# PIC18F06Q20 register map
Vendor: Microchip
Registers are 8-bit, read-write, reset 0x0 unless marked. A register's access mark holds for its fields unless they carry their own. Addresses are absolute, and some are shared; only a register's first bit layout is shown; [hi:lo] are bit positions; {n}, {i} and the like mark numbered series.

## amp_fvr_ts_ctrl
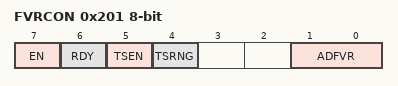
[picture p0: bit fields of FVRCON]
0x201 FVRCON reset not defined — (power-on value xx00--00)
  [7] EN — Zero-Cross Detect Software Enable bit
  [6] RDY ro
  [5] TSEN — Zero-Cross Detect Data Output
  [4] TSRNG — Zero-Cross Detect Polarity bit
  [1:0] ADFVR — Zero-Cross Detect Positive-going Edge Interrupt Enable

## lvd_ctrl
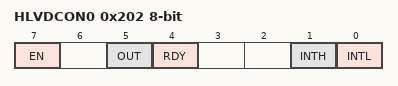
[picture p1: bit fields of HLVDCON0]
0x202 HLVDCON0 reset not defined — (power-on value 0-xx--00)
  [7] EN, [5] OUT ro, [4] RDY ro, [1] INTH, [0] INTL
0x203 HLVDCON1
  [3:0] SEL

## adc_sarcore_mp_ctrl
0x215 ADLTHL
  [7:0] LTH
0x216 ADLTHH
  [7:0] LTH
0x217 ADUTHL
  [7:0] UTH
0x218 ADUTHH
  [7:0] UTH
0x219 ADERRL ro reset not defined — (power-on value xxxxxxxx)
  [7:0] ERR
0x21A ADERRH ro reset not defined — (power-on value xxxxxxxx)
  [7:0] ERR
0x21B ADSTPTL
  [7:0] STPT
0x21C ADSTPTH
  [7:0] STPT
0x21D ADFLTRL ro reset not defined — (power-on value xxxxxxxx)
  [7:0] FLTR
0x21E ADFLTRH ro reset not defined — (power-on value xxxxxxxx)
  [7:0] FLTR
0x21F ADACCL reset not defined — (power-on value xxxxxxxx)
  [7:0] ACC
0x220 ADACCH reset not defined — (power-on value xxxxxxxx)
  [7:0] ACC
0x222 ADCNT
  [7:0] CNT
0x223 ADRPT
  [7:0] RPT
0x224 ADPREVL ro reset not defined — (power-on value xxxxxxxx)
  [7:0] PREV
0x225 ADPREVH ro reset not defined — (power-on value xxxxxxxx)
  [7:0] PREV
0x226 ADRESL reset not defined — (power-on value xxxxxxxx)
  [7:0] RES
0x227 ADRESH reset not defined — (power-on value xxxxxxxx)
  [7:0] RES
0x228 ADPCH
  [5:0] PCH
0x229 ADNCH
  [5:0] NCH
0x22A ADACQL
  [7:0] ACQ
0x22B ADACQH
  [4:0] ACQ
0x22C ADCAP
  [4:0] CAP
0x22D ADPREL
  [7:0] PRE
0x22E ADPREH
  [4:0] PRE
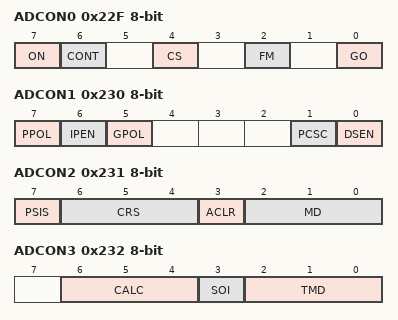
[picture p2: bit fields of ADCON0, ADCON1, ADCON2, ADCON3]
0x22F ADCON0
  [7] ON, [6] CONT, [4] CS, [2] FM, [0] GO
0x230 ADCON1
  [7] PPOL, [6] IPEN, [5] GPOL, [1] PCSC, [0] DSEN
0x231 ADCON2
  [7] PSIS, [6:4] CRS, [3] ACLR, [2:0] MD
0x232 ADCON3
  [6:4] CALC, [3] SOI, [2:0] TMD
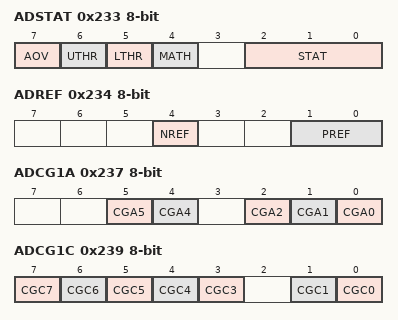
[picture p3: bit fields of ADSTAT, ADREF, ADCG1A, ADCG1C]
0x233 ADSTAT
  [7] AOV ro
  [6] UTHR ro
  [5] LTHR ro
  [4] MATH — (can only be cleared)
  [2:0] STAT ro
0x234 ADREF
  [4] NREF, [1:0] PREF
0x235 ADACT
  [5:0] ACT
0x236 ADCLK
  [5:0] CS
0x237 ADCG1A — ADC CHANNEL GROUP A REGISTER
  [5] CGA5, [4] CGA4, [2] CGA2, [1] CGA1, [0] CGA0
0x239 ADCG1C — ADC CHANNEL GROUP C REGISTER
  [n] CGC{n} (n=3..7), [1] CGC1, [0] CGC0

## pmd
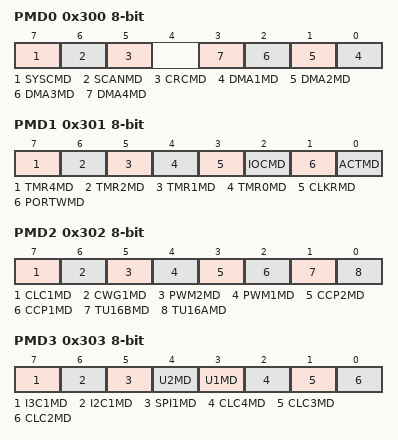
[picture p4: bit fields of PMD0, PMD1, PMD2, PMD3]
0x300 PMD0
  [7] SYSCMD, [6] SCANMD, [5] CRCMD, [n-1] DMA{n}MD (n=1..4)
0x301 PMD1
  [7] TMR4MD, [6] TMR2MD, [5] TMR1MD, [4] TMR0MD, [3] CLKRMD, [2] IOCMD, [1] PORTWMD, [0] ACTMD
0x302 PMD2
  [7] CLC1MD, [6] CWG1MD, [5] PWM2MD, [4] PWM1MD, [3] CCP2MD, [2] CCP1MD, [1] TU16BMD, [0] TU16AMD
0x303 PMD3
  [7] I3C1MD, [6] I2C1MD, [5] SPI1MD, [4] U2MD, [3] U1MD, [2] CLC4MD, [1] CLC3MD, [0] CLC2MD
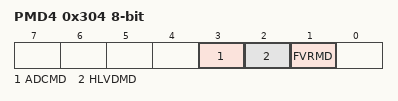
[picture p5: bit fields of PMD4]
0x304 PMD4 reset not defined — (power-on value ----0x0-)
  [3] ADCMD, [2] HLVDMD, [1] FVRMD

## DOS_xxxxx_pps_mid_v2_output_8bit
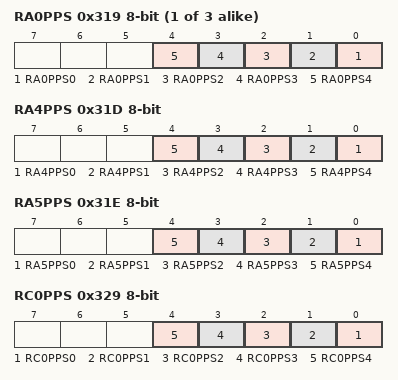
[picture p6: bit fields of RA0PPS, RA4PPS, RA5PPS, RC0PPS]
{0x319+i} RA{i}PPS (i=0..2)
  [n] RA{i}PPS{n} (n=0..4)
0x31D RA4PPS
  [n] RA4PPS{n} (n=0..4)
0x31E RA5PPS
  [n] RA5PPS{n} (n=0..4)
0x329 RC0PPS
  [n] RC0PPS{n} (n=0..4)
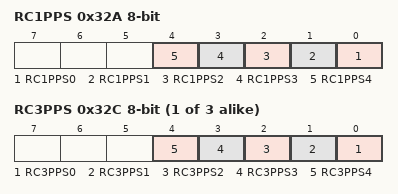
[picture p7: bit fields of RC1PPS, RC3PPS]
0x32A RC1PPS
  [n] RC1PPS{n} (n=0..4)
{0x329+i} RC{i}PPS (i=3..5)
  [n] RC{i}PPS{n} (n=0..4)

## pps_mid
0x352 INT0PPS reset 0x2
  [4:0] INT0PPS
0x353 INT1PPS reset 0x4
  [4:0] INT1PPS
0x354 INT2PPS reset 0x5
  [4:0] INT2PPS
0x355 T0CKIPPS reset 0x2
  [4:0] T0CKIPPS
0x356 T1CKIPPS reset 0x5
  [4:0] T1CKIPPS
0x357 T1GPPS reset 0x4
  [4:0] T1GPPS
0x360 T2INPPS reset 0x5
  [4:0] T2INPPS
0x361 T4INPPS reset 0x11
  [4:0] T4INPPS
0x365 TUIN0PPS reset 0x1
  [4:0] TUIN0PPS
0x366 TUIN1PPS reset 0x10
  [4:0] TUIN1PPS
0x369 CCP1PPS reset 0x15
  [4:0] CCP1PPS
0x36A CCP2PPS reset 0x13
  [4:0] CCP2PPS
0x384 PWMIN0PPS reset 0x15
  [4:0] PWMIN0PPS
0x385 PWMIN1PPS reset 0x13
  [4:0] PWMIN1PPS
0x386 PWM1ERSPPS reset 0x5
  [4:0] PWM1ERSPPS
0x387 PWM2ERSPPS reset 0x11
  [4:0] PWM2ERSPPS
0x399 CWG1PPS reset 0x2
  [4:0] CWG1INPPS
0x39D CLCIN0PPS reset 0x13
  [4:0] CLCIN0PPS
0x39E CLCIN1PPS reset 0x14
  [4:0] CLCIN1PPS
0x39F CLCIN2PPS reset 0x11
  [4:0] CLCIN2PPS
0x3A0 CLCIN3PPS reset 0x5
  [4:0] CLCIN3PPS
0x3A1 U1CTSPPS reset 0x14
  [4:0] U1CTSPPS
0x3A2 U1RXPPS reset 0x15
  [4:0] U1RXPPS
0x3A3 U2CTSPPS reset 0x10
  [4:0] U2CTSPPS
0x3A4 U2RXPPS reset 0x11
  [4:0] U2RXPPS
0x3A7 SPI1SCKPPS reset 0x10
  [4:0] SPI1SCKPPS
0x3A8 SPI1SDIPPS reset 0x11
  [4:0] SPI1SDIPPS
0x3A9 SPI1SSPPS reset 0x13
  [4:0] SPI1SSPPS
0x3AD I2C1SCLPPS reset 0x10
  [4:0] I2C1SCLPPS
0x3AE I2C1SDAPPS reset 0x11
  [4:0] I2C1SDAPPS
0x3B1 ADACTPPS reset 0x13
  [4:0] ADACTPPS
